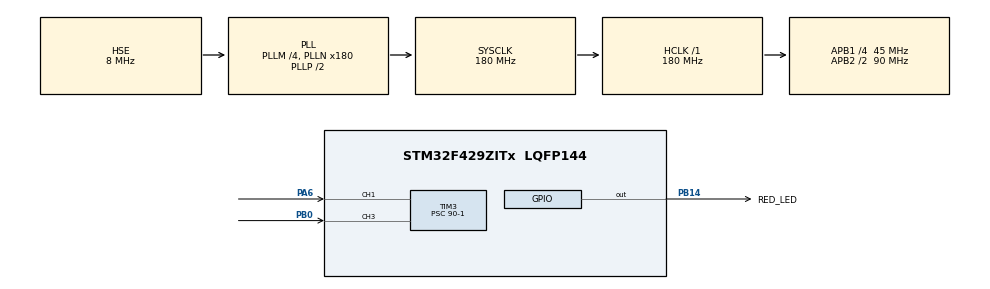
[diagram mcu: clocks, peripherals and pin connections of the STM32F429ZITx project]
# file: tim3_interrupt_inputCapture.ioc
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Mcu.Family=STM32F4
Mcu.Name=STM32F429ZITx
Mcu.Package=LQFP144
NVIC.PriorityGroup=NVIC_PRIORITYGROUP_4
NVIC.TIM3_IRQn=true\:0\:0\:false\:false\:true\:true\:true\:true
PA13.Mode=Serial_Wire
PA13.Signal=SYS_JTMS-SWDIO
PA14.Mode=Serial_Wire
PA14.Signal=SYS_JTCK-SWCLK
PA6.Signal=S_TIM3_CH1
PB0.Signal=S_TIM3_CH3
PB14.GPIO_Label=RED_LED
PB14.Signal=GPIO_Output
PH0/OSC_IN.Mode=HSE-External-Oscillator
PH0/OSC_IN.Signal=RCC_OSC_IN
PH1/OSC_OUT.Mode=HSE-External-Oscillator
PH1/OSC_OUT.Signal=RCC_OSC_OUT
ProjectManager.HeapSize=0x200
ProjectManager.StackSize=0x400
ProjectManager.TargetToolchain=STM32CubeIDE
RCC.48MHZClocksFreq_Value=90000000
RCC.AHBFreq_Value=180000000
RCC.APB1CLKDivider=RCC_HCLK_DIV4
RCC.APB1Freq_Value=45000000
RCC.APB1TimFreq_Value=90000000
RCC.APB2CLKDivider=RCC_HCLK_DIV2
RCC.APB2Freq_Value=90000000
RCC.APB2TimFreq_Value=180000000
RCC.CortexFreq_Value=180000000
RCC.HCLKFreq_Value=180000000
RCC.HSE_VALUE=8000000
RCC.HSI_VALUE=16000000
RCC.LSE_VALUE=32768
RCC.PLLM=4
RCC.PLLN=180
RCC.PLLSourceVirtual=RCC_PLLSOURCE_HSE
RCC.SYSCLKFreq_VALUE=180000000
RCC.SYSCLKSource=RCC_SYSCLKSOURCE_PLLCLK
RCC.VCOOutputFreq_Value=360000000
SH.S_TIM3_CH1.0=TIM3_CH1,TriggerSource_TI1FP1
SH.S_TIM3_CH3.0=TIM3_CH3,Input_Capture3_from_TI3
TIM3.AutoReloadPreload=TIM_AUTORELOAD_PRELOAD_ENABLE
TIM3.Channel-Input_Capture3_from_TI3=TIM_CHANNEL_3
TIM3.Period=30000-1
TIM3.Prescaler=90-1
VP_TIM3_VS_ClockSourceINT.Mode=Internal
VP_TIM3_VS_ControllerModeReset.Mode=Reset Mode
board=custom

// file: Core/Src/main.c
/* USER CODE BEGIN Header */
/**
  ******************************************************************************
  * @file           : main.c
  * @brief          : Main program body
  ******************************************************************************
  * @attention
  *
  * Copyright (c) 2022 STMicroelectronics.
  * All rights reserved.
  *
  * This software is licensed under terms that can be found in the LICENSE file
  * in the root directory of this software component.
  * If no LICENSE file comes with this software, it is provided AS-IS.
  *
  ******************************************************************************
  */
/* USER CODE END Header */
#include "main.h"

 TIM_HandleTypeDef htim3;

/* USER CODE BEGIN PV */

 uint32_t CCR1;

/* USER CODE END PV */

void SystemClock_Config(void);
static void MX_GPIO_Init(void);
static void MX_TIM3_Init(void);

int main(void)
{

  /* MCU Configuration--------------------------------------------------------*/

  /* Reset of all peripherals, Initializes the Flash interface and the Systick. */
  HAL_Init();

  /* Configure the system clock */
  SystemClock_Config();

  /* Initialize all configured peripherals */
  MX_GPIO_Init();
  MX_TIM3_Init();
  /* USER CODE BEGIN 2 */

  HAL_TIM_IC_Start_IT(&htim3, TIM_CHANNEL_3);

  /* USER CODE END 2 */

  /* Infinite loop */
  /* USER CODE BEGIN WHILE */
  while (1)
  {

	  HAL_GPIO_TogglePin(RED_LED_GPIO_Port, RED_LED_Pin);
	  HAL_Delay(500);
    /* USER CODE END WHILE */

  }
}

void SystemClock_Config(void)
{
  RCC_OscInitTypeDef RCC_OscInitStruct = {0};
  RCC_ClkInitTypeDef RCC_ClkInitStruct = {0};

  /** Configure the main internal regulator output voltage
  */
  __HAL_RCC_PWR_CLK_ENABLE();
  __HAL_PWR_VOLTAGESCALING_CONFIG(PWR_REGULATOR_VOLTAGE_SCALE1);

  /** Initializes the RCC Oscillators according to the specified parameters
  * in the RCC_OscInitTypeDef structure.
  */
  RCC_OscInitStruct.OscillatorType = RCC_OSCILLATORTYPE_HSE;
  RCC_OscInitStruct.HSEState = RCC_HSE_ON;
  RCC_OscInitStruct.PLL.PLLState = RCC_PLL_ON;
  RCC_OscInitStruct.PLL.PLLSource = RCC_PLLSOURCE_HSE;
  RCC_OscInitStruct.PLL.PLLM = 4;
  RCC_OscInitStruct.PLL.PLLN = 180;
  RCC_OscInitStruct.PLL.PLLP = RCC_PLLP_DIV2;
  RCC_OscInitStruct.PLL.PLLQ = 4;
  if (HAL_RCC_OscConfig(&RCC_OscInitStruct) != HAL_OK)
  {
    Error_Handler();
  }

  /** Activate the Over-Drive mode
  */
  if (HAL_PWREx_EnableOverDrive() != HAL_OK)
  {
    Error_Handler();
  }

  /** Initializes the CPU, AHB and APB buses clocks
  */
  RCC_ClkInitStruct.ClockType = RCC_CLOCKTYPE_HCLK|RCC_CLOCKTYPE_SYSCLK
                              |RCC_CLOCKTYPE_PCLK1|RCC_CLOCKTYPE_PCLK2;
  RCC_ClkInitStruct.SYSCLKSource = RCC_SYSCLKSOURCE_PLLCLK;
  RCC_ClkInitStruct.AHBCLKDivider = RCC_SYSCLK_DIV1;
  RCC_ClkInitStruct.APB1CLKDivider = RCC_HCLK_DIV4;
  RCC_ClkInitStruct.APB2CLKDivider = RCC_HCLK_DIV2;

  if (HAL_RCC_ClockConfig(&RCC_ClkInitStruct, FLASH_LATENCY_5) != HAL_OK)
  {
    Error_Handler();
  }
}

static void MX_TIM3_Init(void)
{

  TIM_ClockConfigTypeDef sClockSourceConfig = {0};
  TIM_SlaveConfigTypeDef sSlaveConfig = {0};
  TIM_MasterConfigTypeDef sMasterConfig = {0};
  TIM_IC_InitTypeDef sConfigIC = {0};

  htim3.Instance = TIM3;
  htim3.Init.Prescaler = 90-1;
  htim3.Init.CounterMode = TIM_COUNTERMODE_UP;
  htim3.Init.Period = 30000-1;
  htim3.Init.ClockDivision = TIM_CLOCKDIVISION_DIV1;
  htim3.Init.AutoReloadPreload = TIM_AUTORELOAD_PRELOAD_ENABLE;
  if (HAL_TIM_Base_Init(&htim3) != HAL_OK)
  {
    Error_Handler();
  }
  sClockSourceConfig.ClockSource = TIM_CLOCKSOURCE_INTERNAL;
  if (HAL_TIM_ConfigClockSource(&htim3, &sClockSourceConfig) != HAL_OK)
  {
    Error_Handler();
  }
  if (HAL_TIM_IC_Init(&htim3) != HAL_OK)
  {
    Error_Handler();
  }
  sSlaveConfig.SlaveMode = TIM_SLAVEMODE_RESET;
  sSlaveConfig.InputTrigger = TIM_TS_TI1FP1;
  sSlaveConfig.TriggerPolarity = TIM_TRIGGERPOLARITY_RISING;
  sSlaveConfig.TriggerFilter = 0;
  if (HAL_TIM_SlaveConfigSynchro(&htim3, &sSlaveConfig) != HAL_OK)
  {
    Error_Handler();
  }
  sMasterConfig.MasterOutputTrigger = TIM_TRGO_RESET;
  sMasterConfig.MasterSlaveMode = TIM_MASTERSLAVEMODE_DISABLE;
  if (HAL_TIMEx_MasterConfigSynchronization(&htim3, &sMasterConfig) != HAL_OK)
  {
    Error_Handler();
  }
  sConfigIC.ICPolarity = TIM_INPUTCHANNELPOLARITY_RISING;
  sConfigIC.ICSelection = TIM_ICSELECTION_DIRECTTI;
  sConfigIC.ICPrescaler = TIM_ICPSC_DIV1;
  sConfigIC.ICFilter = 0;
  if (HAL_TIM_IC_ConfigChannel(&htim3, &sConfigIC, TIM_CHANNEL_3) != HAL_OK)
  {
    Error_Handler();
  }

}

static void MX_GPIO_Init(void)
{
  GPIO_InitTypeDef GPIO_InitStruct = {0};

  /* GPIO Ports Clock Enable */
  __HAL_RCC_GPIOH_CLK_ENABLE();
  __HAL_RCC_GPIOA_CLK_ENABLE();
  __HAL_RCC_GPIOB_CLK_ENABLE();

  /*Configure GPIO pin Output Level */
  HAL_GPIO_WritePin(RED_LED_GPIO_Port, RED_LED_Pin, GPIO_PIN_RESET);

  /*Configure GPIO pin : RED_LED_Pin */
  GPIO_InitStruct.Pin = RED_LED_Pin;
  GPIO_InitStruct.Mode = GPIO_MODE_OUTPUT_PP;
  GPIO_InitStruct.Pull = GPIO_NOPULL;
  GPIO_InitStruct.Speed = GPIO_SPEED_FREQ_LOW;
  HAL_GPIO_Init(RED_LED_GPIO_Port, &GPIO_InitStruct);

}

/* USER CODE BEGIN 4 */

void HAL_TIM_IC_CaptureCallback(TIM_HandleTypeDef *htim)
{

	CCR1 = HAL_TIM_ReadCapturedValue(&htim3, TIM_CHANNEL_3);

}

/* USER CODE END 4 */

void Error_Handler(void)
{
  __disable_irq();
  while (1)
  {
  }
}
